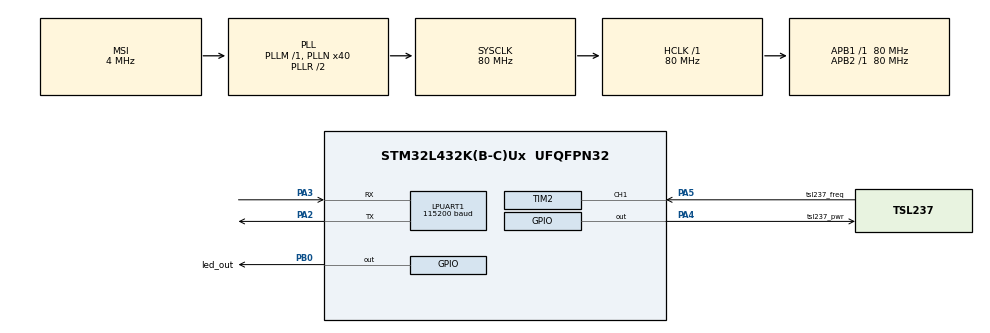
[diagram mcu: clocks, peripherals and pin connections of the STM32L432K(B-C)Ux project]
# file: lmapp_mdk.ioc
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LPUART1.BaudRate=115200
LPUART1.WordLength=UART_WORDLENGTH_8B
Mcu.Family=STM32L4
Mcu.Name=STM32L432K(B-C)Ux
Mcu.Package=UFQFPN32
NVIC.PriorityGroup=NVIC_PRIORITYGROUP_4
PA13\ (JTMS-SWDIO).Mode=Trace_Asynchronous_SW
PA13\ (JTMS-SWDIO).Signal=SYS_JTMS-SWDIO
PA14\ (JTCK-SWCLK).Mode=Trace_Asynchronous_SW
PA14\ (JTCK-SWCLK).Signal=SYS_JTCK-SWCLK
PA2.Mode=Asynchronous
PA2.Signal=LPUART1_TX
PA3.Mode=Asynchronous
PA3.Signal=LPUART1_RX
PA4.GPIO_Label=tsl237_pwr
PA4.Signal=GPIO_Output
PA5.GPIO_Label=tsl237_freq
PA5.Signal=S_TIM2_CH1
PB0.GPIO_Label=led_out
PB0.Signal=GPIO_Output
PB3\ (JTDO-TRACESWO).Mode=Trace_Asynchronous_SW
PB3\ (JTDO-TRACESWO).Signal=SYS_JTDO-SWO
PC14-OSC32_IN\ (PC14).GPIO_Label=oscillator_in
PC14-OSC32_IN\ (PC14).Mode=LSE-External-Clock-Source
PC14-OSC32_IN\ (PC14).Signal=RCC_OSC32_IN
ProjectManager.HeapSize=0x200
ProjectManager.StackSize=0x400
ProjectManager.TargetToolchain=MDK-ARM V5.27
RCC.ADCFreq_Value=48000000
RCC.AHBFreq_Value=80000000
RCC.APB1Freq_Value=80000000
RCC.APB1TimFreq_Value=80000000
RCC.APB2Freq_Value=80000000
RCC.APB2TimFreq_Value=80000000
RCC.CortexFreq_Value=80000000
RCC.HCLKFreq_Value=80000000
RCC.HSE_VALUE=8000000
RCC.HSI48_VALUE=48000000
RCC.HSI_VALUE=16000000
RCC.LSE_VALUE=1000
RCC.MSI_VALUE=4000000
RCC.PLLN=40
RCC.PLLSAI1N=24
RCC.SYSCLKFreq_VALUE=80000000
RCC.SYSCLKSource=RCC_SYSCLKSOURCE_PLLCLK
RCC.USBFreq_Value=48000000
RCC.VCOOutputFreq_Value=160000000
SH.S_TIM2_CH1.0=TIM2_CH1,Input_Capture1_from_TI1
TIM2.Channel-Input_Capture1_from_TI1=TIM_CHANNEL_1
board=custom

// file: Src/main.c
/* USER CODE BEGIN Header */
/**
  ******************************************************************************
  * @file           : main.c
  * @brief          : Main program body
  ******************************************************************************
  * @attention
  *
  * <h2><center>&copy; Copyright (c) 2019 STMicroelectronics.
  * All rights reserved.</center></h2>
  *
  * This software component is licensed by ST under BSD 3-Clause license,
  * the "License"; You may not use this file except in compliance with the
  * License. You may obtain a copy of the License at:
  *                        opensource.org/licenses/BSD-3-Clause
  *
  ******************************************************************************
  */
/* USER CODE END Header */

#include "main.h"

/* USER CODE BEGIN Includes */
#include "RTE_Components.h"
#include  CMSIS_device_header
#include "cmsis_os2.h"

/* USER CODE END Includes */

UART_HandleTypeDef hlpuart1;

TIM_HandleTypeDef htim2;

/* USER CODE BEGIN PV */
// Here is a test commit.

/* USER CODE END PV */

void SystemClock_Config(void);
static void MX_GPIO_Init(void);
static void MX_TIM2_Init(void);
static void MX_LPUART1_UART_Init(void);

/* USER CODE BEGIN 0 */
void app_main(void *argument) {
  for (;;){}
}

/* USER CODE END 0 */

int main(void)
{

  /* MCU Configuration--------------------------------------------------------*/

  /* Reset of all peripherals, Initializes the Flash interface and the Systick. */
  HAL_Init();

  /* Configure the system clock */
  SystemClock_Config();

  /* Initialize all configured peripherals */
  MX_GPIO_Init();
  MX_TIM2_Init();
  MX_LPUART1_UART_Init();
  /* USER CODE BEGIN 2 */
  osKernelInitialize();
  osThreadNew(app_main, NULL,  NULL);
  osKernelStart();

  /* USER CODE END 2 */

  /* Infinite loop */
  while (1)
  {
  // Here is a poke

  }
}

void SystemClock_Config(void)
{
  RCC_OscInitTypeDef RCC_OscInitStruct = {0};
  RCC_ClkInitTypeDef RCC_ClkInitStruct = {0};
  RCC_PeriphCLKInitTypeDef PeriphClkInit = {0};

  /** Initializes the CPU, AHB and APB busses clocks
  */
  RCC_OscInitStruct.OscillatorType = RCC_OSCILLATORTYPE_LSE|RCC_OSCILLATORTYPE_MSI;
  RCC_OscInitStruct.LSEState = RCC_LSE_BYPASS;
  RCC_OscInitStruct.MSIState = RCC_MSI_ON;
  RCC_OscInitStruct.MSICalibrationValue = 0;
  RCC_OscInitStruct.MSIClockRange = RCC_MSIRANGE_6;
  RCC_OscInitStruct.PLL.PLLState = RCC_PLL_ON;
  RCC_OscInitStruct.PLL.PLLSource = RCC_PLLSOURCE_MSI;
  RCC_OscInitStruct.PLL.PLLM = 1;
  RCC_OscInitStruct.PLL.PLLN = 40;
  RCC_OscInitStruct.PLL.PLLP = RCC_PLLP_DIV7;
  RCC_OscInitStruct.PLL.PLLQ = RCC_PLLQ_DIV2;
  RCC_OscInitStruct.PLL.PLLR = RCC_PLLR_DIV2;
  if (HAL_RCC_OscConfig(&RCC_OscInitStruct) != HAL_OK)
  {
    Error_Handler();
  }
  /** Initializes the CPU, AHB and APB busses clocks
  */
  RCC_ClkInitStruct.ClockType = RCC_CLOCKTYPE_HCLK|RCC_CLOCKTYPE_SYSCLK
                              |RCC_CLOCKTYPE_PCLK1|RCC_CLOCKTYPE_PCLK2;
  RCC_ClkInitStruct.SYSCLKSource = RCC_SYSCLKSOURCE_PLLCLK;
  RCC_ClkInitStruct.AHBCLKDivider = RCC_SYSCLK_DIV1;
  RCC_ClkInitStruct.APB1CLKDivider = RCC_HCLK_DIV1;
  RCC_ClkInitStruct.APB2CLKDivider = RCC_HCLK_DIV1;

  if (HAL_RCC_ClockConfig(&RCC_ClkInitStruct, FLASH_LATENCY_4) != HAL_OK)
  {
    Error_Handler();
  }
  PeriphClkInit.PeriphClockSelection = RCC_PERIPHCLK_LPUART1;
  PeriphClkInit.Lpuart1ClockSelection = RCC_LPUART1CLKSOURCE_PCLK1;
  if (HAL_RCCEx_PeriphCLKConfig(&PeriphClkInit) != HAL_OK)
  {
    Error_Handler();
  }
  /** Configure the main internal regulator output voltage
  */
  if (HAL_PWREx_ControlVoltageScaling(PWR_REGULATOR_VOLTAGE_SCALE1) != HAL_OK)
  {
    Error_Handler();
  }
  /** Enable MSI Auto calibration
  */
  HAL_RCCEx_EnableMSIPLLMode();
}

static void MX_LPUART1_UART_Init(void)
{

  hlpuart1.Instance = LPUART1;
  hlpuart1.Init.BaudRate = 115200;
  hlpuart1.Init.WordLength = UART_WORDLENGTH_8B;
  hlpuart1.Init.StopBits = UART_STOPBITS_1;
  hlpuart1.Init.Parity = UART_PARITY_NONE;
  hlpuart1.Init.Mode = UART_MODE_TX_RX;
  hlpuart1.Init.HwFlowCtl = UART_HWCONTROL_NONE;
  hlpuart1.Init.OneBitSampling = UART_ONE_BIT_SAMPLE_DISABLE;
  hlpuart1.AdvancedInit.AdvFeatureInit = UART_ADVFEATURE_NO_INIT;
  if (HAL_UART_Init(&hlpuart1) != HAL_OK)
  {
    Error_Handler();
  }

}

static void MX_TIM2_Init(void)
{

  TIM_MasterConfigTypeDef sMasterConfig = {0};
  TIM_IC_InitTypeDef sConfigIC = {0};

  htim2.Instance = TIM2;
  htim2.Init.Prescaler = 0;
  htim2.Init.CounterMode = TIM_COUNTERMODE_UP;
  htim2.Init.Period = 0;
  htim2.Init.ClockDivision = TIM_CLOCKDIVISION_DIV1;
  htim2.Init.AutoReloadPreload = TIM_AUTORELOAD_PRELOAD_DISABLE;
  if (HAL_TIM_IC_Init(&htim2) != HAL_OK)
  {
    Error_Handler();
  }
  sMasterConfig.MasterOutputTrigger = TIM_TRGO_RESET;
  sMasterConfig.MasterSlaveMode = TIM_MASTERSLAVEMODE_DISABLE;
  if (HAL_TIMEx_MasterConfigSynchronization(&htim2, &sMasterConfig) != HAL_OK)
  {
    Error_Handler();
  }
  sConfigIC.ICPolarity = TIM_INPUTCHANNELPOLARITY_RISING;
  sConfigIC.ICSelection = TIM_ICSELECTION_DIRECTTI;
  sConfigIC.ICPrescaler = TIM_ICPSC_DIV1;
  sConfigIC.ICFilter = 0;
  if (HAL_TIM_IC_ConfigChannel(&htim2, &sConfigIC, TIM_CHANNEL_1) != HAL_OK)
  {
    Error_Handler();
  }

}

static void MX_GPIO_Init(void)
{
  GPIO_InitTypeDef GPIO_InitStruct = {0};

  /* GPIO Ports Clock Enable */
  __HAL_RCC_GPIOC_CLK_ENABLE();
  __HAL_RCC_GPIOA_CLK_ENABLE();
  __HAL_RCC_GPIOB_CLK_ENABLE();

  /*Configure GPIO pin Output Level */
  HAL_GPIO_WritePin(tsl237_pwr_GPIO_Port, tsl237_pwr_Pin, GPIO_PIN_RESET);

  /*Configure GPIO pin Output Level */
  HAL_GPIO_WritePin(led_out_GPIO_Port, led_out_Pin, GPIO_PIN_RESET);

  /*Configure GPIO pin : tsl237_pwr_Pin */
  GPIO_InitStruct.Pin = tsl237_pwr_Pin;
  GPIO_InitStruct.Mode = GPIO_MODE_OUTPUT_PP;
  GPIO_InitStruct.Pull = GPIO_NOPULL;
  GPIO_InitStruct.Speed = GPIO_SPEED_FREQ_LOW;
  HAL_GPIO_Init(tsl237_pwr_GPIO_Port, &GPIO_InitStruct);

  /*Configure GPIO pin : led_out_Pin */
  GPIO_InitStruct.Pin = led_out_Pin;
  GPIO_InitStruct.Mode = GPIO_MODE_OUTPUT_PP;
  GPIO_InitStruct.Pull = GPIO_NOPULL;
  GPIO_InitStruct.Speed = GPIO_SPEED_FREQ_LOW;
  HAL_GPIO_Init(led_out_GPIO_Port, &GPIO_InitStruct);

}

void Error_Handler(void)
{
}

/************************ (C) COPYRIGHT STMicroelectronics *****END OF FILE****/
